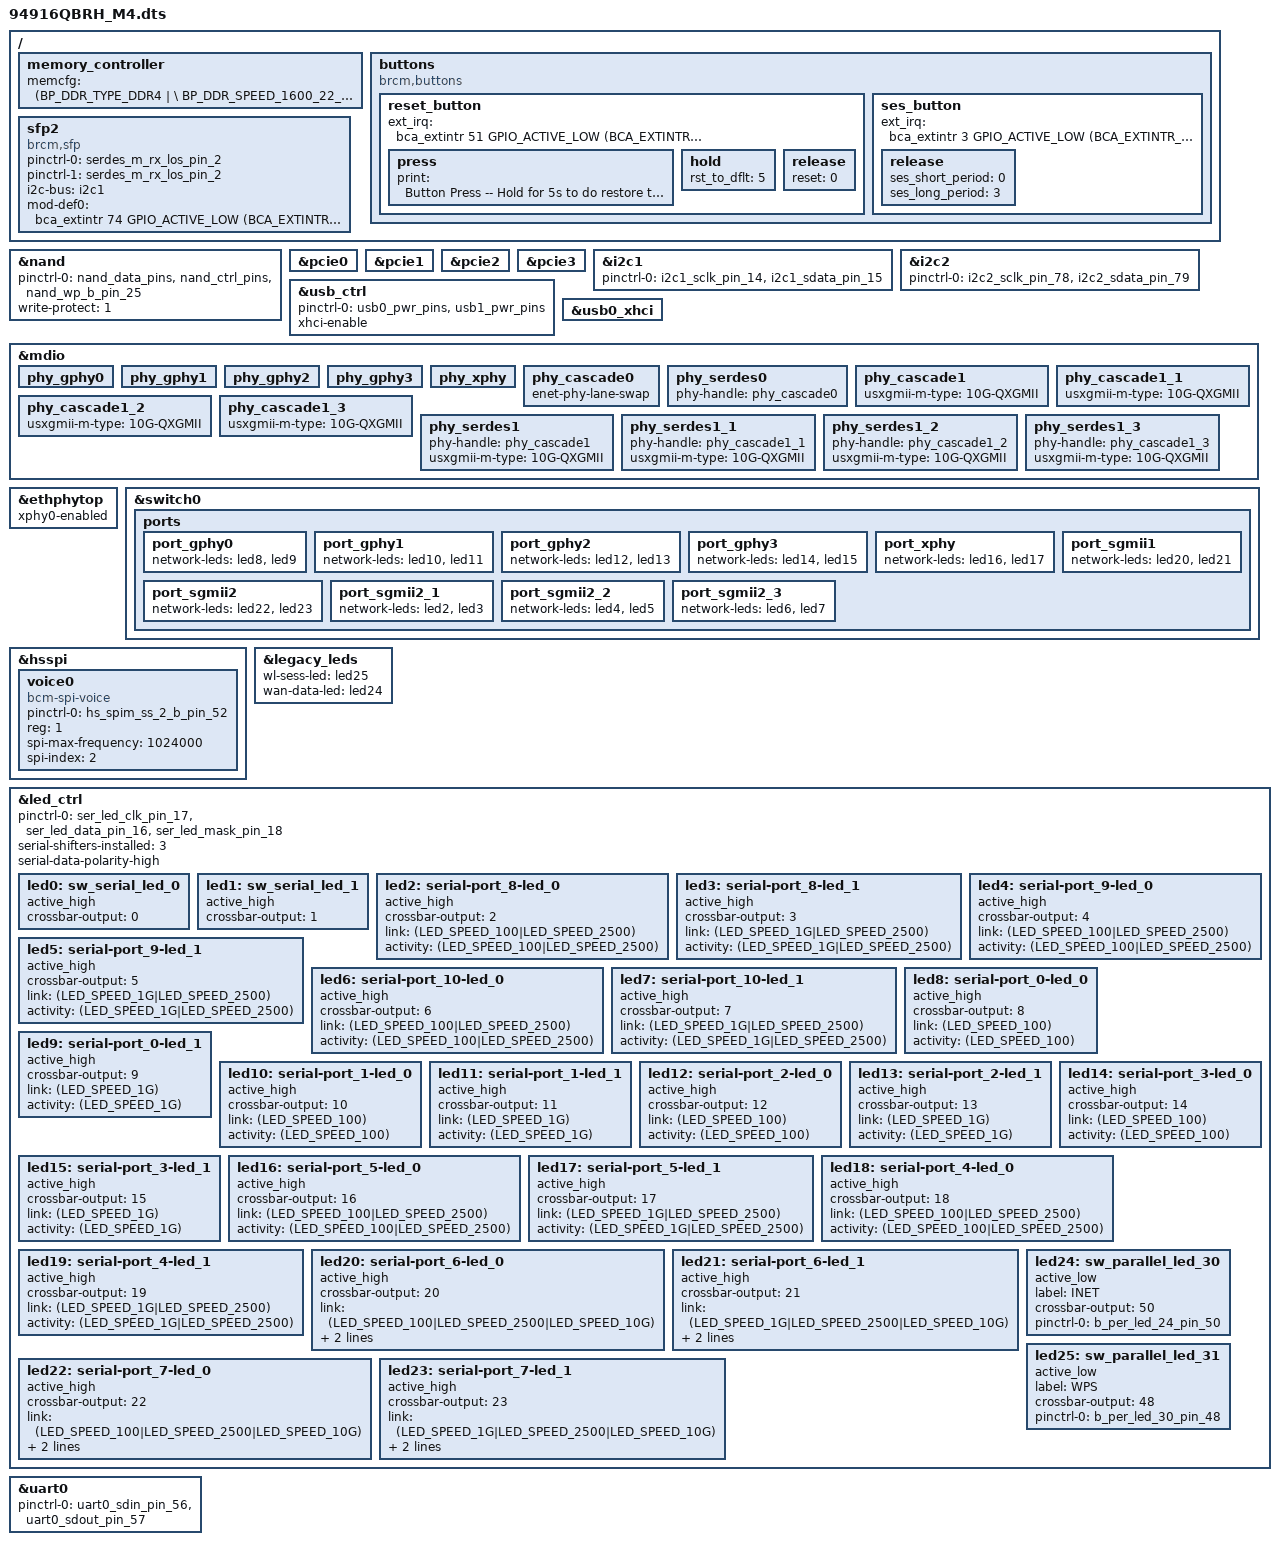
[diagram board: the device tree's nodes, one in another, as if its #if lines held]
#include "6813.dtsi"
#include "../bcm_voice.dtsi"

/ {
	memory_controller {
		memcfg = <(BP_DDR_TYPE_DDR4       | \
			BP_DDR_SPEED_1600_22_22_22    | \
			BP_DDR_TOTAL_SIZE_4096MB      | \
			BP_DDR_DEVICE_WIDTH_16        | \
			BP_DDR_TOTAL_WIDTH_32BIT      | \
			BP_DDR_6813_DEFAULT          | \
			BP_DDR_CONFIG_DEBUG)>;
	};

	buttons: buttons {
		compatible = "brcm,buttons";
		reset_button {
			ext_irq = <&bca_extintr 51 GPIO_ACTIVE_LOW (BCA_EXTINTR_TYPE_LOW_LEVEL | BCA_EXTINTR_TYPE_SENSE_EDGE)>;
			press {
				print = "Button Press -- Hold for 5s to do restore to default";
			};
			hold {
				rst_to_dflt = <5>;
			};
			release {
				reset = <0>;
			};	
		};
		ses_button {
			ext_irq = <&bca_extintr 3 GPIO_ACTIVE_LOW (BCA_EXTINTR_TYPE_LOW_LEVEL | BCA_EXTINTR_TYPE_SENSE_EDGE)>;
			release {
				ses_short_period = <0>;
				ses_long_period = <3>;
			};
		};		
	};

	sfp2: sfp2 {
		compatible = "brcm,sfp";
		pinctrl-names = "default", "rx-sd";
		pinctrl-0 = <&serdes_m_rx_los_pin_2>;
		pinctrl-1 = <&serdes_m_rx_los_pin_2>;
		
		i2c-bus = <&i2c1>;
		mod-def0 = <&bca_extintr 74 GPIO_ACTIVE_LOW (BCA_EXTINTR_TYPE_BOTH_EDGE | BCA_EXTINTR_TYPE_SENSE_EDGE)>;
	};

};

&nand {
	pinctrl-0 = <&nand_data_pins &nand_ctrl_pins &nand_wp_b_pin_25>;
	write-protect = <1>;
	status = "okay";
};

#if defined(CONFIG_BCM_PCIE_HCD) || defined(CONFIG_BCM_PCIE_HCD_MODULE)
/**********************************************************************/
/* GPIO: Add one define per GPIO (individual or shared) regulator     */
/*       - Skip if no GPIO regulators in use                          */
/**********************************************************************/
#define PCIE0_REG_GPIO    1     /* SLEEP_0 for vreg_pcie0 node */
#define PCIE1_REG_GPIO    12    /* SLEEP_1 for vreg_pcie1 node */
#define PCIE2_REG_GPIO    77    /* SLEEP_2 for vreg_pcie2 node */
#define PCIE3_REG_GPIO    76    /* SLEEP_3 for vreg_pcie3 node */

#include "../bcm_wlan_regulator.dtsi"

/**********************************************************************/
/* Shared: Add brcm,supply-names = "vreg-pcieX" for shared PCIe nodes */
/*         - Skip if not using shared GPIO regulators                 */
/**********************************************************************/

/**********************************************************************/
/* PCIe: Add status = "okay" for each PCIe slots of this board       */
/*       - Skip if this is a derivative board (already done in base)  */
/**********************************************************************/
&pcie0 {
	status = "okay";
};
&pcie1 {
	status = "okay";
};
&pcie2 {
	status = "okay";
};
&pcie3 {
	status = "okay";
};
#endif //#if defined(CONFIG_BCM_PCIE_HCD) || defined(CONFIG_BCM_PCIE_HCD_MODULE)

&i2c1 {
	pinctrl-names = "default";
	pinctrl-0 = <&i2c1_sclk_pin_14 &i2c1_sdata_pin_15>;
	status = "okay";
};
&i2c2 {
	pinctrl-names = "default";
	pinctrl-0 = <&i2c2_sclk_pin_78 &i2c2_sdata_pin_79>;
	status = "okay";
};

&usb_ctrl {
	pinctrl-names = "default";
	pinctrl-0 = <&usb0_pwr_pins &usb1_pwr_pins>;
	status = "okay";
	xhci-enable;
};
&usb0_xhci {
	status = "okay";
};

&mdio {
    /* Port PHY mapping:
            port_gphy0 <----> phy_gphy0
            port_gphy1 <----> phy_gphy1
            port_gphy2 <----> phy_gphy2
            port_gphy3 <----> phy_gphy3
            port_xphy <-----> phy_xphy
            port_sgmii1 <---> phy_serdes0   - phy_cascade0
            port_sgmii2 <---> phy_serdes1   - phy_cascade1
            port_sgmii2_1 <-> phy_serdes1_1 - phy_cascade1_1
            port_sgmii2_2 <-> phy_serdes1_2 - phy_cascade1_2
            port_sgmii2_3 <-> phy_serdes1_3 - phy_cascade1_3
     */
	phy_gphy0 {
		status = "okay";
	};

	phy_gphy1 {
		status = "okay";
	};

	phy_gphy2 {
		status = "okay";
	};

	phy_gphy3 {
		status = "okay";
	};
	phy_xphy {
		status = "okay";
	};

	phy_cascade0 {
		enet-phy-lane-swap;
		status = "okay";
	};

	phy_serdes0 {
		phy-handle = <&phy_cascade0>;
		status = "okay";
	};

	phy_cascade1 {
		usxgmii-m-type = "10G-QXGMII";  /* types: 10G-SXGMII 10G-DXGMII 10G-QXGMII 5G-SXGMII 5G-DXGMII 2.5G-SXGMII */
		status = "okay";
	};

	phy_cascade1_1 {
		usxgmii-m-type = "10G-QXGMII";  /* types: 10G-SXGMII 10G-DXGMII 10G-QXGMII 5G-SXGMII 5G-DXGMII 2.5G-SXGMII */
		status = "okay";
	};

	phy_cascade1_2 {
		usxgmii-m-type = "10G-QXGMII";  /* types: 10G-SXGMII 10G-DXGMII 10G-QXGMII 5G-SXGMII 5G-DXGMII 2.5G-SXGMII */
		status = "okay";
	};

	phy_cascade1_3 {
		usxgmii-m-type = "10G-QXGMII";  /* types: 10G-SXGMII 10G-DXGMII 10G-QXGMII 5G-SXGMII 5G-DXGMII 2.5G-SXGMII */
		status = "okay";
	};

	phy_serdes1 {
		phy-handle = <&phy_cascade1>;
		usxgmii-m-type = "10G-QXGMII";  /* types: 10G-SXGMII 10G-DXGMII 10G-QXGMII 5G-SXGMII 5G-DXGMII 2.5G-SXGMII */
		status = "okay";
	};

	phy_serdes1_1 {
		phy-handle = <&phy_cascade1_1>;
		usxgmii-m-type = "10G-QXGMII";  /* types: 10G-SXGMII 10G-DXGMII 10G-QXGMII 5G-SXGMII 5G-DXGMII 2.5G-SXGMII */
		status = "okay";
	};

	phy_serdes1_2 {
		phy-handle = <&phy_cascade1_2>;
		usxgmii-m-type = "10G-QXGMII";  /* types: 10G-SXGMII 10G-DXGMII 10G-QXGMII 5G-SXGMII 5G-DXGMII 2.5G-SXGMII */
		status = "okay";
	};

	phy_serdes1_3 {
		phy-handle = <&phy_cascade1_3>;
		usxgmii-m-type = "10G-QXGMII";  /* types: 10G-SXGMII 10G-DXGMII 10G-QXGMII 5G-SXGMII 5G-DXGMII 2.5G-SXGMII */
		status = "okay";
	};

};

&ethphytop {
	xphy0-enabled;
	status = "okay";
};

&switch0 {
	ports {
		port_gphy0 {
			network-leds = <&led8 &led9>;
			status = "okay";
		};

		port_gphy1 {
			network-leds = <&led10 &led11>;
			status = "okay";
		};

		port_gphy2 {
			network-leds = <&led12 &led13>;
			status = "okay";
		};

		port_gphy3 {
			network-leds = <&led14 &led15>;
			status = "okay";
		};

		port_xphy {
			network-leds = <&led16 &led17>;
			status = "okay";
		};

		port_sgmii1 {
			network-leds = <&led20 &led21>;
			status = "okay";
		};
		port_sgmii2 {
			network-leds = <&led22 &led23>;
			status = "okay";
		};

		port_sgmii2_1 {
			network-leds = <&led2 &led3>;
			status = "okay";
		};

		port_sgmii2_2 {
			network-leds = <&led4 &led5>;
			status = "okay";
		};

		port_sgmii2_3 {
			network-leds = <&led6 &led7>;
			status = "okay";
		};

	};
};

&hsspi {
	status = "okay";
	voice0 {
		pinctrl-0 = <&hs_spim_ss_2_b_pin_52>;
		pinctrl-names = "default";
		compatible = "bcm-spi-voice";
		reg = <1>; /* chip select 1 */
		spi-max-frequency = <1024000>;
		spi-index = <2>;/* voice header index */
	};
};

&legacy_leds {
    wl-sess-led = <&led25>;
    wan-data-led = <&led24>;
};

&led_ctrl {
    pinctrl-names = "default";
    pinctrl-0 = <&ser_led_clk_pin_17 &ser_led_data_pin_16 &ser_led_mask_pin_18>;
    serial-shifters-installed = <3>;
    serial-data-polarity-high;

    led0: sw_serial_led_0 { /* place holder since we just need to use this bit for serial leds */ 
        active_high;
        crossbar-output = <0>;
        status = "okay";
    };
    led1: sw_serial_led_1 { /* place holder since we just need to use this bit for serial leds */
        active_high;
        crossbar-output = <1>;
        status = "okay";
    };

    led2: serial-port_8-led_0 { /* SGMII2-M2, M4 */
        active_high;
        crossbar-output = <2>;
        link = <(LED_SPEED_100|LED_SPEED_2500)>;
        activity = <(LED_SPEED_100|LED_SPEED_2500)>;
        status = "okay";
    };
    led3: serial-port_8-led_1 { /* SGMII2-M2, M4 */
        active_high;
        crossbar-output = <3>;
        link = <(LED_SPEED_1G|LED_SPEED_2500)>;
        activity = <(LED_SPEED_1G|LED_SPEED_2500)>;
        status = "okay";
    };
    led4: serial-port_9-led_0 { /* SGMII2-M4 */
        active_high;
        crossbar-output = <4>;
        link = <(LED_SPEED_100|LED_SPEED_2500)>;
        activity = <(LED_SPEED_100|LED_SPEED_2500)>;
        status = "okay";
    };
    led5: serial-port_9-led_1 { /* SGMII2-M4 */
        active_high;
        crossbar-output = <5>;
        link = <(LED_SPEED_1G|LED_SPEED_2500)>;
        activity = <(LED_SPEED_1G|LED_SPEED_2500)>;
        status = "okay";
    };
    led6: serial-port_10-led_0 { /* SGMII2-M4 */
        active_high;
        crossbar-output = <6>;
        link = <(LED_SPEED_100|LED_SPEED_2500)>;
        activity = <(LED_SPEED_100|LED_SPEED_2500)>;
        status = "okay";
    };
    led7: serial-port_10-led_1 { /* SGMII2-M4 */
        active_high;
        crossbar-output = <7>;
        link = <(LED_SPEED_1G|LED_SPEED_2500)>;
        activity = <(LED_SPEED_1G|LED_SPEED_2500)>;
        status = "okay";
    };

    led8: serial-port_0-led_0 {
        active_high;
        crossbar-output = <8>;
        link = <(LED_SPEED_100)>;
        activity = <(LED_SPEED_100)>;
        status = "okay";
    };
    led9: serial-port_0-led_1 {
        active_high;
        crossbar-output = <9>;
        link = <(LED_SPEED_1G)>;
        activity = <(LED_SPEED_1G)>;
        status = "okay";
    };
    led10: serial-port_1-led_0 {
        active_high;
        crossbar-output = <10>;
        link = <(LED_SPEED_100)>;
        activity = <(LED_SPEED_100)>;
        status = "okay";
    };
    led11: serial-port_1-led_1 {
        active_high;
        crossbar-output = <11>;
        link = <(LED_SPEED_1G)>;
        activity = <(LED_SPEED_1G)>;
        status = "okay";
    };
    led12: serial-port_2-led_0 {
        active_high;
        crossbar-output = <12>;
        link = <(LED_SPEED_100)>;
        activity = <(LED_SPEED_100)>;
        status = "okay";
    };
    led13: serial-port_2-led_1 {
        active_high;
        crossbar-output = <13>;
        link = <(LED_SPEED_1G)>;
        activity = <(LED_SPEED_1G)>;
        status = "okay";
    };
    led14: serial-port_3-led_0 {
        active_high;
        crossbar-output = <14>;
        link = <(LED_SPEED_100)>;
        activity = <(LED_SPEED_100)>;
        status = "okay";
    };
    led15: serial-port_3-led_1 {
        active_high;
        crossbar-output = <15>;
        link = <(LED_SPEED_1G)>;
        activity = <(LED_SPEED_1G)>;
        status = "okay";
    };
    led16: serial-port_5-led_0 {
        active_high;
        crossbar-output = <16>;
        link = <(LED_SPEED_100|LED_SPEED_2500)>;
        activity = <(LED_SPEED_100|LED_SPEED_2500)>;
        status = "okay";
    };
    led17: serial-port_5-led_1 {
        active_high;
        crossbar-output = <17>;
        link = <(LED_SPEED_1G|LED_SPEED_2500)>;
        activity = <(LED_SPEED_1G|LED_SPEED_2500)>;
        status = "okay";
    };
    led18: serial-port_4-led_0 {
        active_high;
        crossbar-output = <18>;
        link = <(LED_SPEED_100|LED_SPEED_2500)>;
        activity = <(LED_SPEED_100|LED_SPEED_2500)>;
        status = "okay";
    };
    led19: serial-port_4-led_1 {
        active_high;
        crossbar-output = <19>;
        link = <(LED_SPEED_1G|LED_SPEED_2500)>;
        activity = <(LED_SPEED_1G|LED_SPEED_2500)>;
        status = "okay";
    };
    led20: serial-port_6-led_0 {
        active_high;
        crossbar-output = <20>;
        link = <(LED_SPEED_100|LED_SPEED_2500|LED_SPEED_10G)>;
        activity = <(LED_SPEED_100|LED_SPEED_2500|LED_SPEED_10G)>;
        status = "okay";
    };
    led21: serial-port_6-led_1 {
        active_high;
        crossbar-output = <21>;
        link = <(LED_SPEED_1G|LED_SPEED_2500|LED_SPEED_10G)>;
        activity = <(LED_SPEED_1G|LED_SPEED_2500|LED_SPEED_10G)>;
        status = "okay";
    };
    led22: serial-port_7-led_0 { /* SGMII2 */
        active_high;
        crossbar-output = <22>;
        link = <(LED_SPEED_100|LED_SPEED_2500|LED_SPEED_10G)>;
        activity = <(LED_SPEED_100|LED_SPEED_2500|LED_SPEED_10G)>;
        status = "okay";
    };
    led23: serial-port_7-led_1 { /* SGMII2 */
        active_high;
        crossbar-output = <23>;
        link = <(LED_SPEED_1G|LED_SPEED_2500|LED_SPEED_10G)>;
        activity = <(LED_SPEED_1G|LED_SPEED_2500|LED_SPEED_10G)>;
        status = "okay";
    };
    led24: sw_parallel_led_30 {
        active_low;
        label = "INET";
        crossbar-output = <50>;
        pinctrl-0=<&b_per_led_24_pin_50>;
        status = "okay";
    };
    led25: sw_parallel_led_31 {
        active_low;
        label = "WPS";
        crossbar-output = <48>;
        pinctrl-0=<&b_per_led_30_pin_48>;
        status = "okay";
    };
};

&uart0 {
        pinctrl-names = "default";
        pinctrl-0 = <&uart0_sdin_pin_56 &uart0_sdout_pin_57 >;
        status = "okay";
};

